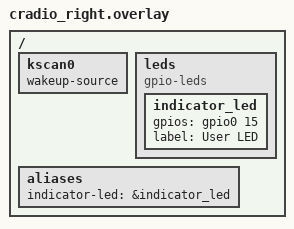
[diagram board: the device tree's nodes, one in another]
/ {
    kscan0 {
        wakeup-source;
    };
    
    leds {
        compatible = "gpio-leds";
        indicator_led: indicator_led {
            gpios = <&gpio0 15 GPIO_ACTIVE_HIGH>;
            label = "User LED";
        };
    };

    aliases {
        indicator-led = &indicator_led;  
    };
};

